# FM33FK5XX register map
File version: 1.0
CPU: Cortex-M33 r1p0, little endian, MPU, FPU, 3 interrupt priority bits
Registers are 32-bit, read-write, reset 0x0 unless marked. A register's access mark holds for its fields unless they carry their own. Offsets are from the block's base; [hi:lo] are bit positions; {n}, {i} and the like mark numbered series; 'fields as' and 'values as' point back to an identical list.

## SVD — SVD module information
Base 0x40021400
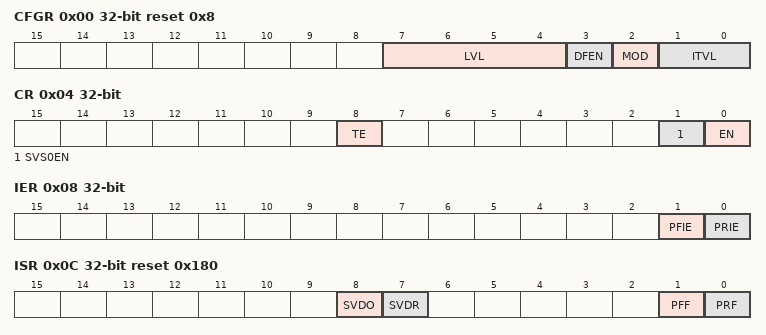
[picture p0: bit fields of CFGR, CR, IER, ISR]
0x00 CFGR reset 0x8 — SVDConfigRegister
  [7:4] LVL — LVL field description
  [3] DFEN — DFEN field description
  [2] MOD — MOD field description
  [1:0] ITVL — ITVL field description
0x04 CR — SVDControlRegister
  [8] TE — TE field description
  [1] SVS0EN — SVS0EN field description
  [0] EN — EN field description
0x08 IER — SVDInterruptEnableRegister
  [1] PFIE — PFIE field description
  [0] PRIE — PRIE field description
0x0C ISR access per field reset 0x180 — SVDInterruptStatusRegister
  [8] SVDO ro — SVDO field description
  [7] SVDR ro — SVDR field description
  [1] PFF rw — PFF field description
  [0] PRF rw — PRF field description
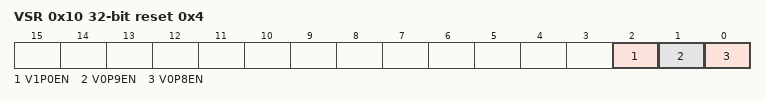
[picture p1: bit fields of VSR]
0x10 VSR reset 0x4 — SVDreferenceVoltageSelectRegister
  [2] V1P0EN — V1P0EN field description
  [1] V0P9EN — V0P9EN field description
  [0] V0P8EN — V0P8EN field description

## AES — AES module information
Base 0x4001B800
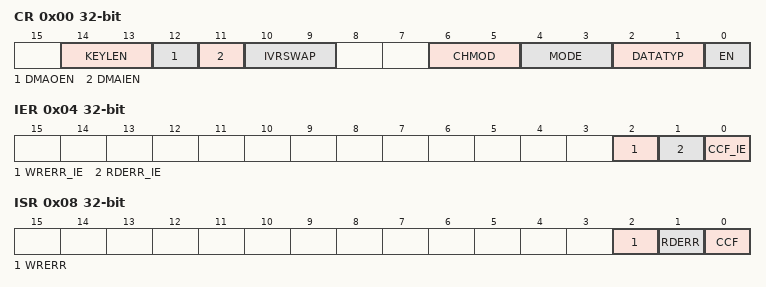
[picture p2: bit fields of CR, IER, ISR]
0x00 CR — AESControlRegister
  [14:13] KEYLEN — KEYLEN field description
  [12] DMAOEN — DMAOEN field description
  [11] DMAIEN — DMAIEN field description
  [10:9] IVRSWAP — IVRSWAP field description
  [6:5] CHMOD — CHMOD field description
  [4:3] MODE — MODE field description
  [2:1] DATATYP — DATATYP field description
  [0] EN — EN field description
0x04 IER — AESInterruptEnableRegister
  [2] WRERR_IE — WRERR_IE field description
  [1] RDERR_IE — RDERR_IE field description
  [0] CCF_IE — CCF_IE field description
0x08 ISR — AESInterruptStatusRegister
  [2] WRERR — WRERR field description
  [1] RDERR — RDERR field description
  [0] CCF — CCF field description
0x0C DIR — AESDataInputRegister
  [31:0] DIN — DIN field description
0x10 DOR ro — AESDataOutputRegister
  [31:0] DOUT — DOUT field description
{0x14+4i} KEY{i} (i=0..7) — AESKeyRegister{i}
  [31:0] KEYx — KEYx field description
{0x34+4i} IVR{i} (i=0..3) — AESInitialVectorRegister{i}
  [31:0] IVRx — IVRx field description
{0x44+4i} H{i} (i=0..3) — AESMultHparameterRegister{i}
  [31:0] Hx — Hx field description

## RNG — RNG module information
Base 0x4001BC00
0x00 CR — RandomNumberGeneratorControlRegister
  [0] RNGEN — RNGEN field description
0x04 DOR ro — RandomNumberGeneratorDataOutputRegister
  [31:0] RNGOUT — RNGOUT field description
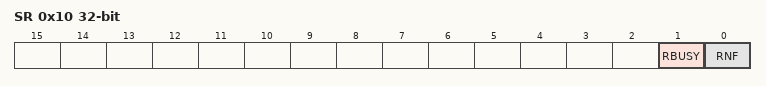
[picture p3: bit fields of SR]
0x10 SR access per field — RandomNumberGeneratorStatusRegister
  [1] RBUSY ro — RBUSY field description
  [0] RNF rw — RNF field description
0x14 CRCCR — CRCControlRegister
  [0] CRCEN — CRCEN field description
0x18 CRCDIR — CRCDatainputRegister
  [31:0] CRCIN — CRCIN field description
0x1C CRCSR — CRCStatusRegister
  [0] CRCDONE — CRCDONE field description

## COMP — COMP module information
Base 0x40022400
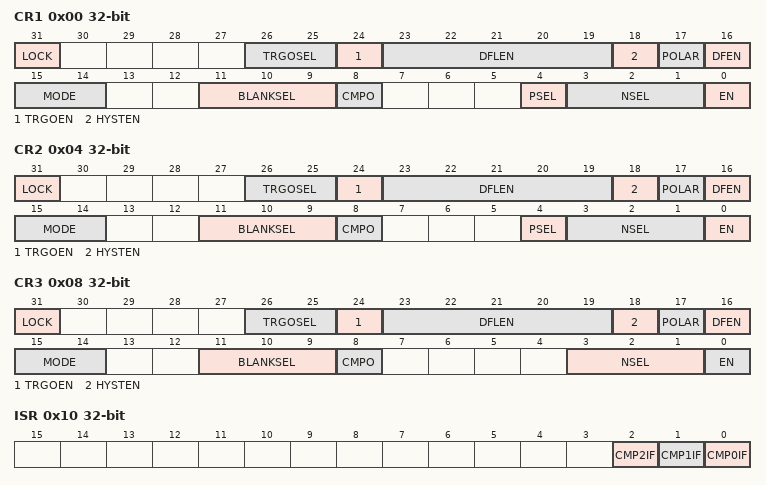
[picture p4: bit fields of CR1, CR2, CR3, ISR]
0x00 CR1 access per field
  [31] LOCK rw — LOCK field description
  [26:25] TRGOSEL rw — TRGOSEL field description
  [24] TRGOEN rw — TRGOEN field description
  [23:19] DFLEN rw — DFLEN field description
  [18] HYSTEN rw — HYSTEN field description
  [17] POLAR rw — POLAR field description
  [16] DFEN rw — DFEN field description
  [15:14] MODE rw — MODE field description
  [11:9] BLANKSEL rw — BLANKSEL field description
  [8] CMPO ro — CMPO field description
  [4] PSEL rw — PSEL field description
  [3:1] NSEL rw — NSEL field description
  [0] EN rw — EN field description
0x04 CR2 access per field
  fields as CR1
0x08 CR3 access per field
  [31] LOCK rw — LOCK field description
  [26:25] TRGOSEL rw — TRGOSEL field description
  [24] TRGOEN rw — TRGOEN field description
  [23:19] DFLEN rw — DFLEN field description
  [18] HYSTEN rw — HYSTEN field description
  [17] POLAR rw — POLAR field description
  [16] DFEN rw — DFEN field description
  [15:14] MODE rw — MODE field description
  [11:9] BLANKSEL rw — BLANKSEL field description
  [8] CMPO ro — CMPO field description
  [3:1] NSEL rw — NSEL field description
  [0] EN rw — EN field description
0x10 ISR
  [2] CMP2IF — CMP2IF field description
  [1] CMP1IF — CMP1IF field description
  [0] CMP0IF — CMP0IF field description
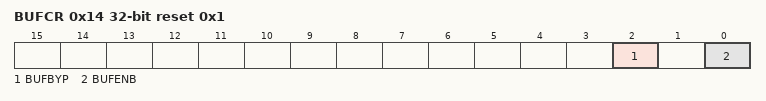
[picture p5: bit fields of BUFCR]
0x14 BUFCR reset 0x1
  [2] BUFBYP — BUFBYP field description
  [0] BUFENB — BUFENB field description
